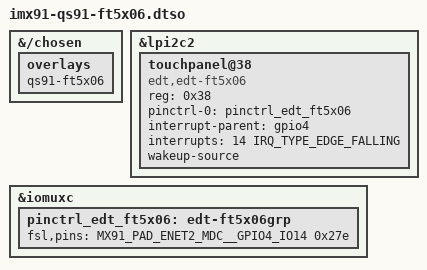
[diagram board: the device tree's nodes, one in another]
// SPDX-License-Identifier: (GPL-2.0 OR MIT)
/*
 * Copyright 2025 Lothar Waßmann <LW@KARO-electronics.de>
 *
 */

/dts-v1/;
/plugin/;

#include <dt-bindings/gpio/gpio.h>
#include <dt-bindings/interrupt-controller/irq.h>
#include "imx91-pinfunc.h"

&{/chosen} {
	overlays {
		qs91-ft5x06;
	};
};

&lpi2c2 {
	status = "okay";

	touchpanel@38 {
		compatible = "edt,edt-ft5x06";
		reg = <0x38>;
		pinctrl-names = "default";
		pinctrl-0 = <&pinctrl_edt_ft5x06>;
		interrupt-parent = <&gpio4>;
		interrupts = <14 IRQ_TYPE_EDGE_FALLING>;
		wakeup-source;
	};
};

&iomuxc {
	pinctrl_edt_ft5x06: edt-ft5x06grp {
		fsl,pins = <
			MX91_PAD_ENET2_MDC__GPIO4_IO14		0x27e /* Interrupt */
		>;
	};
};
